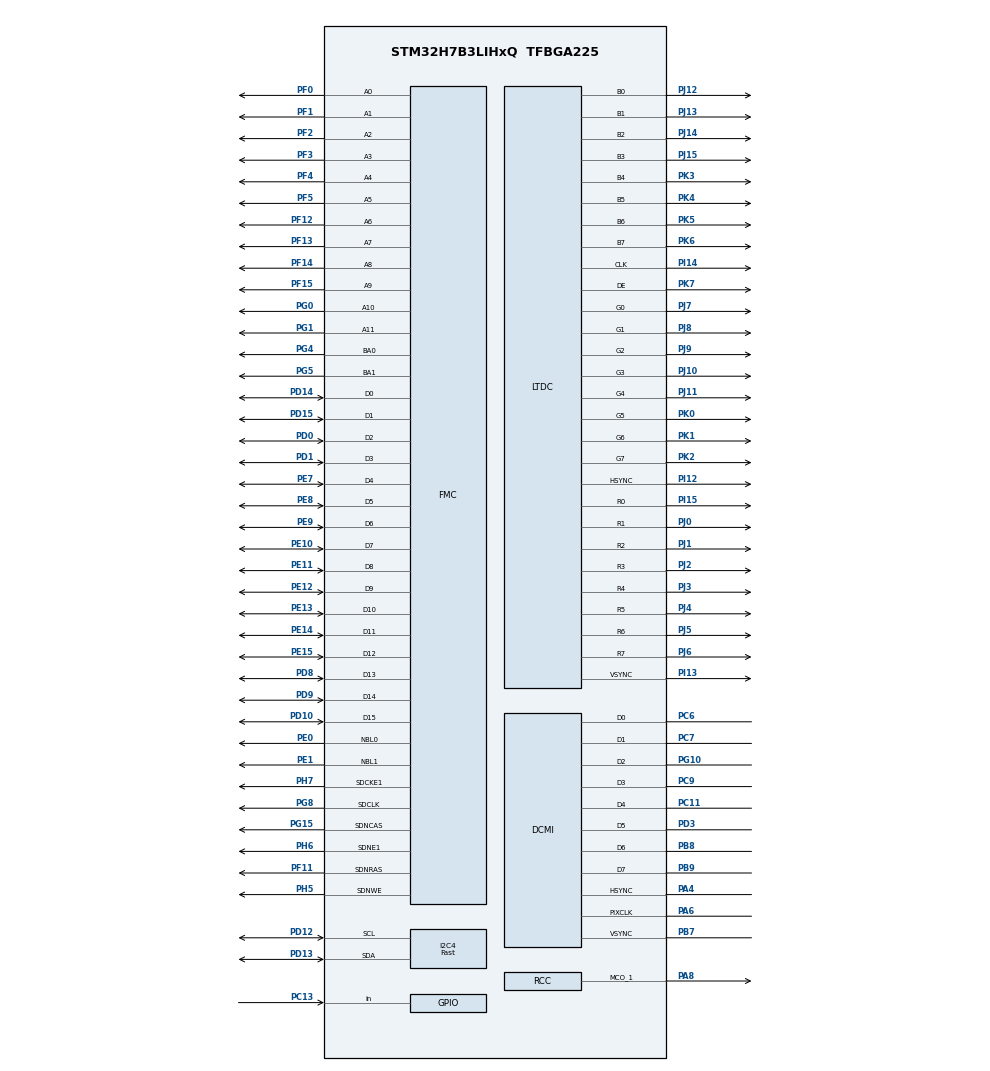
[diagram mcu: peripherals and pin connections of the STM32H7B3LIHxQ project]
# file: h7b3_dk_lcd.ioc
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CORTEX_M7.AccessPermission_S-Cortex_Memory_Protection_Unit_Region1_Settings_S=MPU_REGION_FULL_ACCESS
CORTEX_M7.BaseAddress_S-Cortex_Memory_Protection_Unit_Region1_Settings_S=0xD0000000
CORTEX_M7.Enable_S-Cortex_Memory_Protection_Unit_Region1_Settings_S=MPU_REGION_ENABLE
CORTEX_M7.IsCacheable_S-Cortex_Memory_Protection_Unit_Region1_Settings_S=MPU_ACCESS_CACHEABLE
CORTEX_M7.Size_S-Cortex_Memory_Protection_Unit_Region1_Settings_S=MPU_REGION_SIZE_16MB
CORTEX_M7.default_mode_Activation=1
DCMI.JPEGMode=DCMI_JPEG_DISABLE
DCMI.PCKPolarity=DCMI_PCKPOLARITY_RISING
DCMI.VSPolarity=DCMI_VSPOLARITY_HIGH
DMA2D.InputAlphaForeground=0xFF
DMA2D.InputColorModeForeground=DMA2D_INPUT_RGB565
DMA2D.Mode=DMA2D_M2M_PFC
Dma.DCMI_PSSI.0.Direction=DMA_PERIPH_TO_MEMORY
Dma.DCMI_PSSI.0.EventEnable=DISABLE
Dma.DCMI_PSSI.0.FIFOMode=DMA_FIFOMODE_ENABLE
Dma.DCMI_PSSI.0.FIFOThreshold=DMA_FIFO_THRESHOLD_FULL
Dma.DCMI_PSSI.0.Instance=DMA2_Stream3
Dma.DCMI_PSSI.0.MemBurst=DMA_MBURST_INC4
Dma.DCMI_PSSI.0.MemDataAlignment=DMA_MDATAALIGN_WORD
Dma.DCMI_PSSI.0.MemInc=DMA_MINC_ENABLE
Dma.DCMI_PSSI.0.Mode=DMA_CIRCULAR
Dma.DCMI_PSSI.0.PeriphBurst=DMA_PBURST_SINGLE
Dma.DCMI_PSSI.0.PeriphDataAlignment=DMA_PDATAALIGN_WORD
Dma.DCMI_PSSI.0.PeriphInc=DMA_PINC_DISABLE
Dma.DCMI_PSSI.0.Polarity=HAL_DMAMUX_REQ_GEN_RISING
Dma.DCMI_PSSI.0.Priority=DMA_PRIORITY_HIGH
Dma.DCMI_PSSI.0.RequestNumber=1
Dma.DCMI_PSSI.0.SignalID=NONE
Dma.DCMI_PSSI.0.SyncEnable=DISABLE
Dma.DCMI_PSSI.0.SyncPolarity=HAL_DMAMUX_SYNC_NO_EVENT
Dma.DCMI_PSSI.0.SyncRequestNumber=1
Dma.DCMI_PSSI.0.SyncSignalID=NONE
Dma.Request0=DCMI_PSSI
FMC.CASLatency1=FMC_SDRAM_CAS_LATENCY_2
FMC.ColumnBitsNumber1=FMC_SDRAM_COLUMN_BITS_NUM_9
FMC.ExitSelfRefreshDelay1=7
FMC.LoadToActiveDelay1=2
FMC.RCDDelay1=2
FMC.RPDelay1=2
FMC.RPDelay2=2
FMC.ReadBurst1=FMC_SDRAM_RBURST_ENABLE
FMC.ReadBurst2=FMC_SDRAM_RBURST_ENABLE
FMC.ReadPipeDelay1=FMC_SDRAM_RPIPE_DELAY_2
FMC.ReadPipeDelay2=FMC_SDRAM_RPIPE_DELAY_2
FMC.RowCycleDelay1=7
FMC.RowCycleDelay2=7
FMC.SDClockPeriod1=FMC_SDRAM_CLOCK_PERIOD_3
FMC.SDClockPeriod2=FMC_SDRAM_CLOCK_PERIOD_3
FMC.SelfRefreshTime1=4
FMC.WriteRecoveryTime1=3
I2C4.I2C_Speed_Mode=I2C_Fast
I2C4.Timing=0x00D04BFF
LTDC.ActiveH=272
LTDC.ActiveW=480
LTDC.Alpha_L0=255
LTDC.HBP=2
LTDC.HFP=32
LTDC.HSync=41
LTDC.ImageHeight_L0=240
LTDC.ImageWidth_L0=320
LTDC.Layers=0
LTDC.PixelFormat_L0=LTDC_PIXEL_FORMAT_RGB565
LTDC.VSync=10
LTDC.WindowX1_L0=320
LTDC.WindowY1_L0=240
Mcu.Family=STM32H7
Mcu.Name=STM32H7B3LIHxQ
Mcu.Package=TFBGA225
NVIC.DCMI_PSSI_IRQn=true\:10\:0\:true\:false\:true\:true\:true\:true
NVIC.DMA2D_IRQn=true\:0\:0\:false\:false\:true\:true\:true\:true
NVIC.DMA2_Stream3_IRQn=true\:10\:0\:true\:false\:true\:false\:true\:true
NVIC.PriorityGroup=NVIC_PRIORITYGROUP_4
PA13.Mode=Serial_Wire
PA13.Signal=DEBUG_JTMS-SWDIO
PA14.Mode=Serial_Wire
PA14.Signal=DEBUG_JTCK-SWCLK
PA4.GPIO_PuPd=GPIO_PULLUP
PA4.GPIO_Speed=GPIO_SPEED_FREQ_VERY_HIGH
PA4.Mode=Slave_8_bits_External_Synchro
PA4.Signal=DCMI_HSYNC
PA6.GPIO_PuPd=GPIO_PULLUP
PA6.GPIO_Speed=GPIO_SPEED_FREQ_VERY_HIGH
PA6.Mode=Slave_8_bits_External_Synchro
PA6.Signal=DCMI_PIXCLK
PA8.Mode=Clock-out-1
PA8.Signal=RCC_MCO_1
PB7.GPIO_PuPd=GPIO_PULLUP
PB7.GPIO_Speed=GPIO_SPEED_FREQ_VERY_HIGH
PB7.Mode=Slave_8_bits_External_Synchro
PB7.Signal=DCMI_VSYNC
PB8.GPIO_PuPd=GPIO_PULLUP
PB8.GPIO_Speed=GPIO_SPEED_FREQ_VERY_HIGH
PB8.Mode=Slave_8_bits_External_Synchro
PB8.Signal=DCMI_D6
PB9.GPIO_PuPd=GPIO_PULLUP
PB9.GPIO_Speed=GPIO_SPEED_FREQ_VERY_HIGH
PB9.Mode=Slave_8_bits_External_Synchro
PB9.Signal=DCMI_D7
PC11.GPIO_PuPd=GPIO_PULLUP
PC11.GPIO_Speed=GPIO_SPEED_FREQ_VERY_HIGH
PC11.Mode=Slave_8_bits_External_Synchro
PC11.Signal=DCMI_D4
PC13.Signal=GPIO_Input
PC6.GPIO_PuPd=GPIO_PULLUP
PC6.GPIO_Speed=GPIO_SPEED_FREQ_VERY_HIGH
PC6.Mode=Slave_8_bits_External_Synchro
PC6.Signal=DCMI_D0
PC7.GPIO_PuPd=GPIO_PULLUP
PC7.GPIO_Speed=GPIO_SPEED_FREQ_VERY_HIGH
PC7.Mode=Slave_8_bits_External_Synchro
PC7.Signal=DCMI_D1
PC9.GPIO_PuPd=GPIO_PULLUP
PC9.GPIO_Speed=GPIO_SPEED_FREQ_VERY_HIGH
PC9.Mode=Slave_8_bits_External_Synchro
PC9.Signal=DCMI_D3
PD0.Signal=FMC_D2_DA2
PD1.Signal=FMC_D3_DA3
PD10.Signal=FMC_D15_DA15
PD12.GPIO_Speed=GPIO_SPEED_FREQ_HIGH
PD12.Mode=I2C
PD12.Signal=I2C4_SCL
PD13.GPIO_Speed=GPIO_SPEED_FREQ_HIGH
PD13.Mode=I2C
PD13.Signal=I2C4_SDA
PD14.Signal=FMC_D0_DA0
PD15.Signal=FMC_D1_DA1
PD3.GPIO_PuPd=GPIO_PULLUP
PD3.GPIO_Speed=GPIO_SPEED_FREQ_VERY_HIGH
PD3.Mode=Slave_8_bits_External_Synchro
PD3.Signal=DCMI_D5
PD8.Signal=FMC_D13_DA13
PD9.Signal=FMC_D14_DA14
PE0.Signal=FMC_NBL0
PE1.Signal=FMC_NBL1
PE10.Signal=FMC_D7_DA7
PE11.Signal=FMC_D8_DA8
PE12.Signal=FMC_D9_DA9
PE13.Signal=FMC_D10_DA10
PE14.Signal=FMC_D11_DA11
PE15.Signal=FMC_D12_DA12
PE7.Signal=FMC_D4_DA4
PE8.Signal=FMC_D5_DA5
PE9.Signal=FMC_D6_DA6
PF0.Signal=FMC_A0
PF1.Signal=FMC_A1
PF11.Signal=FMC_SDNRAS
PF12.Signal=FMC_A6
PF13.Signal=FMC_A7
PF14.Signal=FMC_A8
PF15.Signal=FMC_A9
PF2.Signal=FMC_A2
PF3.Signal=FMC_A3
PF4.Signal=FMC_A4
PF5.Signal=FMC_A5
PG0.Signal=FMC_A10
PG1.Signal=FMC_A11
PG10.GPIO_PuPd=GPIO_PULLUP
PG10.GPIO_Speed=GPIO_SPEED_FREQ_VERY_HIGH
PG10.Mode=Slave_8_bits_External_Synchro
PG10.Signal=DCMI_D2
PG15.Signal=FMC_SDNCAS
PG4.Signal=FMC_A14_BA0
PG5.Signal=FMC_A15_BA1
PG8.Signal=FMC_SDCLK
PH0-OSC_IN.Mode=HSE-External-Oscillator
PH0-OSC_IN.Signal=RCC_OSC_IN
PH1-OSC_OUT.Mode=HSE-External-Oscillator
PH1-OSC_OUT.Signal=RCC_OSC_OUT
PH5.Signal=FMC_SDNWE
PH6.Mode=SdramChipSelect2_1
PH6.Signal=FMC_SDNE1
PH7.Mode=SdramChipSelect2_1
PH7.Signal=FMC_SDCKE1
PI12.GPIO_Speed=GPIO_SPEED_FREQ_HIGH
PI12.Mode=RGB888
PI12.Signal=LTDC_HSYNC
PI13.GPIO_Speed=GPIO_SPEED_FREQ_HIGH
PI13.Mode=RGB888
PI13.Signal=LTDC_VSYNC
PI14.GPIO_Speed=GPIO_SPEED_FREQ_HIGH
PI14.Mode=RGB888
PI14.Signal=LTDC_CLK
PI15.GPIO_Speed=GPIO_SPEED_FREQ_HIGH
PI15.Mode=RGB888
PI15.Signal=LTDC_R0
PJ0.GPIO_Speed=GPIO_SPEED_FREQ_HIGH
PJ0.Mode=RGB888
PJ0.Signal=LTDC_R1
PJ1.GPIO_Speed=GPIO_SPEED_FREQ_HIGH
PJ1.Mode=RGB888
PJ1.Signal=LTDC_R2
PJ10.GPIO_Speed=GPIO_SPEED_FREQ_HIGH
PJ10.Mode=RGB888
PJ10.Signal=LTDC_G3
PJ11.GPIO_Speed=GPIO_SPEED_FREQ_HIGH
PJ11.Mode=RGB888
PJ11.Signal=LTDC_G4
PJ12.GPIO_Speed=GPIO_SPEED_FREQ_HIGH
PJ12.Mode=RGB888
PJ12.Signal=LTDC_B0
PJ13.GPIO_Speed=GPIO_SPEED_FREQ_HIGH
PJ13.Mode=RGB888
PJ13.Signal=LTDC_B1
PJ14.GPIO_Speed=GPIO_SPEED_FREQ_HIGH
PJ14.Mode=RGB888
PJ14.Signal=LTDC_B2
PJ15.GPIO_Speed=GPIO_SPEED_FREQ_HIGH
PJ15.Mode=RGB888
PJ15.Signal=LTDC_B3
PJ2.GPIO_Speed=GPIO_SPEED_FREQ_HIGH
PJ2.Mode=RGB888
PJ2.Signal=LTDC_R3
PJ3.GPIO_Speed=GPIO_SPEED_FREQ_HIGH
PJ3.Mode=RGB888
PJ3.Signal=LTDC_R4
PJ4.GPIO_Speed=GPIO_SPEED_FREQ_HIGH
PJ4.Mode=RGB888
PJ4.Signal=LTDC_R5
PJ5.GPIO_Speed=GPIO_SPEED_FREQ_HIGH
PJ5.Mode=RGB888
PJ5.Signal=LTDC_R6
PJ6.GPIO_Speed=GPIO_SPEED_FREQ_HIGH
PJ6.Mode=RGB888
PJ6.Signal=LTDC_R7
PJ7.GPIO_Speed=GPIO_SPEED_FREQ_HIGH
PJ7.Mode=RGB888
PJ7.Signal=LTDC_G0
PJ8.GPIO_Speed=GPIO_SPEED_FREQ_HIGH
PJ8.Mode=RGB888
PJ8.Signal=LTDC_G1
PJ9.GPIO_Speed=GPIO_SPEED_FREQ_HIGH
PJ9.Mode=RGB888
PJ9.Signal=LTDC_G2
PK0.GPIO_Speed=GPIO_SPEED_FREQ_HIGH
PK0.Mode=RGB888
PK0.Signal=LTDC_G5
PK1.GPIO_Speed=GPIO_SPEED_FREQ_HIGH
PK1.Mode=RGB888
PK1.Signal=LTDC_G6
PK2.GPIO_Speed=GPIO_SPEED_FREQ_HIGH
PK2.Mode=RGB888
PK2.Signal=LTDC_G7
PK3.GPIO_Speed=GPIO_SPEED_FREQ_HIGH
PK3.Mode=RGB888
PK3.Signal=LTDC_B4
PK4.GPIO_Speed=GPIO_SPEED_FREQ_HIGH
PK4.Mode=RGB888
PK4.Signal=LTDC_B5
PK5.GPIO_Speed=GPIO_SPEED_FREQ_HIGH
PK5.Mode=RGB888
PK5.Signal=LTDC_B6
PK6.GPIO_Speed=GPIO_SPEED_FREQ_HIGH
PK6.Mode=RGB888
PK6.Signal=LTDC_B7
PK7.GPIO_Speed=GPIO_SPEED_FREQ_HIGH
PK7.Mode=RGB888
PK7.Signal=LTDC_DE
ProjectManager.HeapSize=0x400
ProjectManager.StackSize=0x800
ProjectManager.TargetToolchain=STM32CubeIDE
RCC.ADCFreq_Value=200000000
RCC.APB1Freq_Value=140000000
RCC.APB2Freq_Value=140000000
RCC.APB3Freq_Value=140000000
RCC.APB4Freq_Value=140000000
RCC.CDPPRE=RCC_APB3_DIV2
RCC.CDPPRE1=RCC_APB1_DIV2
RCC.CDPPRE2=RCC_APB2_DIV2
RCC.CortexFreq_Value=280000000
RCC.DIVM1=3
RCC.DIVM2=12
RCC.DIVM3=24
RCC.DIVN1=70
RCC.DIVN2=200
RCC.DIVN3=200
RCC.DIVR2=4
RCC.DIVR3=10
RCC.FMCCLockSelection=RCC_FMCCLKSOURCE_PLL2
RCC.HCLKFreq_Value=280000000
RCC.PLL2FRACN=0
RCC.PLL3FRACN=5462
RCC.PLLFRACN=0
RCC.PLLSourceVirtual=RCC_PLLSOURCE_HSE
RCC.RCC_MCO1Source=RCC_MCO1SOURCE_HSE
RCC.SRDPPRE=RCC_APB4_DIV2
RCC.SYSCLKFreq_VALUE=280000000
RCC.SYSCLKSource=RCC_SYSCLKSOURCE_PLLCLK
RCC.USBFreq_Value=280000000
SH.FMC_A0.0=FMC_A0,12b-sda1
SH.FMC_A1.0=FMC_A1,12b-sda1
SH.FMC_A10.0=FMC_A10,12b-sda1
SH.FMC_A11.0=FMC_A11,12b-sda1
SH.FMC_A14_BA0.0=FMC_BA0,FourSdramBanks1
SH.FMC_A15_BA1.0=FMC_BA1,FourSdramBanks1
SH.FMC_A2.0=FMC_A2,12b-sda1
SH.FMC_A3.0=FMC_A3,12b-sda1
SH.FMC_A4.0=FMC_A4,12b-sda1
SH.FMC_A5.0=FMC_A5,12b-sda1
SH.FMC_A6.0=FMC_A6,12b-sda1
SH.FMC_A7.0=FMC_A7,12b-sda1
SH.FMC_A8.0=FMC_A8,12b-sda1
SH.FMC_A9.0=FMC_A9,12b-sda1
SH.FMC_D0_DA0.0=FMC_D0,sd-16b-d1
SH.FMC_D10_DA10.0=FMC_D10,sd-16b-d1
SH.FMC_D11_DA11.0=FMC_D11,sd-16b-d1
SH.FMC_D12_DA12.0=FMC_D12,sd-16b-d1
SH.FMC_D13_DA13.0=FMC_D13,sd-16b-d1
SH.FMC_D14_DA14.0=FMC_D14,sd-16b-d1
SH.FMC_D15_DA15.0=FMC_D15,sd-16b-d1
SH.FMC_D1_DA1.0=FMC_D1,sd-16b-d1
SH.FMC_D2_DA2.0=FMC_D2,sd-16b-d1
SH.FMC_D3_DA3.0=FMC_D3,sd-16b-d1
SH.FMC_D4_DA4.0=FMC_D4,sd-16b-d1
SH.FMC_D5_DA5.0=FMC_D5,sd-16b-d1
SH.FMC_D6_DA6.0=FMC_D6,sd-16b-d1
SH.FMC_D7_DA7.0=FMC_D7,sd-16b-d1
SH.FMC_D8_DA8.0=FMC_D8,sd-16b-d1
SH.FMC_D9_DA9.0=FMC_D9,sd-16b-d1
SH.FMC_NBL0.0=FMC_NBL0,Sd2ByteEnable1
SH.FMC_NBL1.0=FMC_NBL1,Sd2ByteEnable1
SH.FMC_SDCLK.0=FMC_SDCLK,12b-sda1
SH.FMC_SDNCAS.0=FMC_SDNCAS,12b-sda1
SH.FMC_SDNRAS.0=FMC_SDNRAS,12b-sda1
SH.FMC_SDNWE.0=FMC_SDNWE,12b-sda1
VP_DMA2D_VS_DMA2D.Mode=DMA2D_Activate
board=custom

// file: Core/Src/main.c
/* USER CODE BEGIN Header */
/**
  ******************************************************************************
  * @file           : main.c
  * @brief          : Main program body
  ******************************************************************************
  * @attention
  *
  * Copyright (c) 2022 STMicroelectronics.
  * All rights reserved.
  *
  * This software is licensed under terms that can be found in the LICENSE file
  * in the root directory of this software component.
  * If no LICENSE file comes with this software, it is provided AS-IS.
  *
  ******************************************************************************
  */
/* USER CODE END Header */
#include "main.h"
#include "dcmi.h"
#include "dma.h"
#include "dma2d.h"
#include "i2c.h"
#include "ltdc.h"
#include "gpio.h"
#include "fmc.h"

/* USER CODE BEGIN Includes */
#include "lcd_rk043fn48h.h"
#include "image_st_logo.h"
#include "sdram.h"
#include "camera.h"
/* USER CODE END Includes */

void SystemClock_Config(void);
static void MPU_Config(void);

/* USER CODE BEGIN 0 */
uint32_t CameraResolution[4] = {CAMERA_R160x120, CAMERA_R320x240, CAMERA_R480x272, CAMERA_R640x480};
uint32_t CameraResX[4] = {160, 320, 480, 640};
uint32_t CameraResY[4] = {120, 240, 272, 480};
uint32_t CameraResIndex = 3;
/* USER CODE END 0 */

int main(void)
{

  /* MPU Configuration--------------------------------------------------------*/
  MPU_Config();

  /* MCU Configuration--------------------------------------------------------*/

  /* Reset of all peripherals, Initializes the Flash interface and the Systick. */
  HAL_Init();

  /* Configure the system clock */
  SystemClock_Config();

  /* Initialize all configured peripherals */
  MX_GPIO_Init();
  MX_LTDC_Init();
  MX_DCMI_Init();
  MX_DMA_Init();
  MX_I2C4_Init();
  MX_FMC_Init();
  MX_DMA2D_Init();
  /* USER CODE BEGIN 2 */
  SDRAM_Test();
  CAMERA_Init(CameraResIndex,CameraResolution[CameraResIndex],CAMERA_PF_RGB565);
  SDRAM_LCD_REFRESH();
  /* USER CODE END 2 */

  /* Infinite loop */
  /* USER CODE BEGIN WHILE */
  while (1)
  {
    //SDRAM_LCD_REFRESH();
    if (HAL_GPIO_ReadPin(GPIOC, GPIO_PIN_13) == GPIO_PIN_SET)
    {
      HAL_Delay(200);
      CAMERA_Capture_Start(1);
    }
    /* USER CODE END WHILE */

  }
}

void SystemClock_Config(void)
{
  RCC_OscInitTypeDef RCC_OscInitStruct = {0};
  RCC_ClkInitTypeDef RCC_ClkInitStruct = {0};

  /** Supply configuration update enable
  */
  HAL_PWREx_ConfigSupply(PWR_DIRECT_SMPS_SUPPLY);

  /** Configure the main internal regulator output voltage
  */
  __HAL_PWR_VOLTAGESCALING_CONFIG(PWR_REGULATOR_VOLTAGE_SCALE0);

  while(!__HAL_PWR_GET_FLAG(PWR_FLAG_VOSRDY)) {}

  /** Macro to configure the PLL clock source
  */
  __HAL_RCC_PLL_PLLSOURCE_CONFIG(RCC_PLLSOURCE_HSE);

  /** Initializes the RCC Oscillators according to the specified parameters
  * in the RCC_OscInitTypeDef structure.
  */
  RCC_OscInitStruct.OscillatorType = RCC_OSCILLATORTYPE_HSE;
  RCC_OscInitStruct.HSEState = RCC_HSE_ON;
  RCC_OscInitStruct.PLL.PLLState = RCC_PLL_ON;
  RCC_OscInitStruct.PLL.PLLSource = RCC_PLLSOURCE_HSE;
  RCC_OscInitStruct.PLL.PLLM = 3;
  RCC_OscInitStruct.PLL.PLLN = 70;
  RCC_OscInitStruct.PLL.PLLP = 2;
  RCC_OscInitStruct.PLL.PLLQ = 2;
  RCC_OscInitStruct.PLL.PLLR = 2;
  RCC_OscInitStruct.PLL.PLLRGE = RCC_PLL1VCIRANGE_3;
  RCC_OscInitStruct.PLL.PLLVCOSEL = RCC_PLL1VCOWIDE;
  RCC_OscInitStruct.PLL.PLLFRACN = 0;
  if (HAL_RCC_OscConfig(&RCC_OscInitStruct) != HAL_OK)
  {
    Error_Handler();
  }

  /** Initializes the CPU, AHB and APB buses clocks
  */
  RCC_ClkInitStruct.ClockType = RCC_CLOCKTYPE_HCLK|RCC_CLOCKTYPE_SYSCLK
                              |RCC_CLOCKTYPE_PCLK1|RCC_CLOCKTYPE_PCLK2
                              |RCC_CLOCKTYPE_D3PCLK1|RCC_CLOCKTYPE_D1PCLK1;
  RCC_ClkInitStruct.SYSCLKSource = RCC_SYSCLKSOURCE_PLLCLK;
  RCC_ClkInitStruct.SYSCLKDivider = RCC_SYSCLK_DIV1;
  RCC_ClkInitStruct.AHBCLKDivider = RCC_HCLK_DIV1;
  RCC_ClkInitStruct.APB3CLKDivider = RCC_APB3_DIV2;
  RCC_ClkInitStruct.APB1CLKDivider = RCC_APB1_DIV2;
  RCC_ClkInitStruct.APB2CLKDivider = RCC_APB2_DIV2;
  RCC_ClkInitStruct.APB4CLKDivider = RCC_APB4_DIV2;

  if (HAL_RCC_ClockConfig(&RCC_ClkInitStruct, FLASH_LATENCY_7) != HAL_OK)
  {
    Error_Handler();
  }
  HAL_RCC_MCOConfig(RCC_MCO1, RCC_MCO1SOURCE_HSE, RCC_MCODIV_1);
}

/* MPU Configuration */

void MPU_Config(void)
{
  MPU_Region_InitTypeDef MPU_InitStruct = {0};

  /* Disables the MPU */
  HAL_MPU_Disable();

  /** Initializes and configures the Region and the memory to be protected
  */
  MPU_InitStruct.Enable = MPU_REGION_ENABLE;
  MPU_InitStruct.Number = MPU_REGION_NUMBER0;
  MPU_InitStruct.BaseAddress = 0x0;
  MPU_InitStruct.Size = MPU_REGION_SIZE_4GB;
  MPU_InitStruct.SubRegionDisable = 0x87;
  MPU_InitStruct.TypeExtField = MPU_TEX_LEVEL0;
  MPU_InitStruct.AccessPermission = MPU_REGION_NO_ACCESS;
  MPU_InitStruct.DisableExec = MPU_INSTRUCTION_ACCESS_DISABLE;
  MPU_InitStruct.IsShareable = MPU_ACCESS_SHAREABLE;
  MPU_InitStruct.IsCacheable = MPU_ACCESS_NOT_CACHEABLE;
  MPU_InitStruct.IsBufferable = MPU_ACCESS_NOT_BUFFERABLE;

  HAL_MPU_ConfigRegion(&MPU_InitStruct);

  /** Initializes and configures the Region and the memory to be protected
  */
  MPU_InitStruct.Number = MPU_REGION_NUMBER1;
  MPU_InitStruct.BaseAddress = 0xD0000000;
  MPU_InitStruct.Size = MPU_REGION_SIZE_16MB;
  MPU_InitStruct.SubRegionDisable = 0x0;
  MPU_InitStruct.AccessPermission = MPU_REGION_FULL_ACCESS;
  MPU_InitStruct.DisableExec = MPU_INSTRUCTION_ACCESS_ENABLE;
  MPU_InitStruct.IsShareable = MPU_ACCESS_NOT_SHAREABLE;
  MPU_InitStruct.IsCacheable = MPU_ACCESS_CACHEABLE;

  HAL_MPU_ConfigRegion(&MPU_InitStruct);
  /* Enables the MPU */
  HAL_MPU_Enable(MPU_PRIVILEGED_DEFAULT);

}

void Error_Handler(void)
{
  __disable_irq();
  while (1)
  {
  }
}
